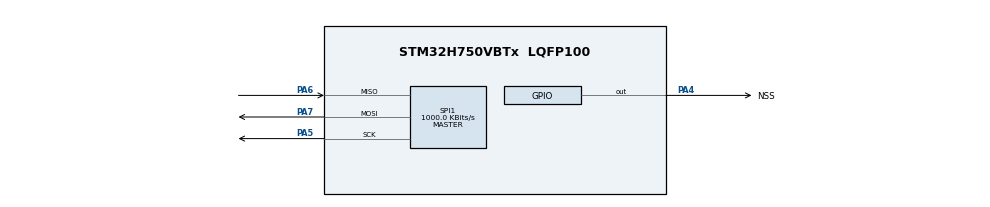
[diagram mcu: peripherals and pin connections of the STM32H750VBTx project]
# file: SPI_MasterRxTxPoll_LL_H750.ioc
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Mcu.Family=STM32H7
Mcu.Name=STM32H750VBTx
Mcu.Package=LQFP100
NVIC.PriorityGroup=NVIC_PRIORITYGROUP_4
PA13\ (JTMS/SWDIO).Mode=Serial_Wire
PA13\ (JTMS/SWDIO).Signal=DEBUG_JTMS-SWDIO
PA14\ (JTCK/SWCLK).Mode=Serial_Wire
PA14\ (JTCK/SWCLK).Signal=DEBUG_JTCK-SWCLK
PA4.GPIO_Label=NSS
PA4.Signal=GPIO_Output
PA5.Mode=Full_Duplex_Master
PA5.Signal=SPI1_SCK
PA6.Mode=Full_Duplex_Master
PA6.Signal=SPI1_MISO
PA7.Mode=Full_Duplex_Master
PA7.Signal=SPI1_MOSI
PH0-OSC_IN\ (PH0).Mode=HSE-External-Oscillator
PH0-OSC_IN\ (PH0).Signal=RCC_OSC_IN
PH1-OSC_OUT\ (PH1).Mode=HSE-External-Oscillator
PH1-OSC_OUT\ (PH1).Signal=RCC_OSC_OUT
ProjectManager.HeapSize=0x200
ProjectManager.StackSize=0x400
ProjectManager.TargetToolchain=STM32CubeIDE
RCC.ADCFreq_Value=128000000
RCC.APB1Freq_Value=120000000
RCC.APB2Freq_Value=120000000
RCC.APB3Freq_Value=120000000
RCC.APB4Freq_Value=120000000
RCC.CortexFreq_Value=240000000
RCC.DIVM1=25
RCC.DIVM2=25
RCC.DIVN1=480
RCC.DIVN2=256
RCC.HCLKFreq_Value=120000000
RCC.HPRE=RCC_HCLK_DIV2
RCC.PLLSourceVirtual=RCC_PLLSOURCE_HSE
RCC.SPI123CLockSelection=RCC_SPI123CLKSOURCE_PLL2
RCC.SYSCLKFreq_VALUE=240000000
RCC.SYSCLKSource=RCC_SYSCLKSOURCE_PLLCLK
RCC.USBFreq_Value=240000000
SPI1.BaudRatePrescaler=SPI_BAUDRATEPRESCALER_128
SPI1.CLKPolarity=SPI_POLARITY_HIGH
SPI1.CalculateBaudRate=1000.0 KBits/s
SPI1.DataSize=SPI_DATASIZE_8BIT
SPI1.Direction=SPI_DIRECTION_2LINES
SPI1.Mode=SPI_MODE_MASTER
SPI1.NSSPolarity=SPI_NSS_POLARITY_HIGH
SPI1.VirtualType=VM_MASTER
board=custom

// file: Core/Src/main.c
/* USER CODE BEGIN Header */
/**
  ******************************************************************************
  * @file           : main.c
  * @brief          : Main program body
  ******************************************************************************
  * @attention
  *
  * Copyright (c) 2023 STMicroelectronics.
  * All rights reserved.
  *
  * This software is licensed under terms that can be found in the LICENSE file
  * in the root directory of this software component.
  * If no LICENSE file comes with this software, it is provided AS-IS.
  *
  ******************************************************************************
  */
/* USER CODE END Header */
#include "main.h"

void SystemClock_Config(void);
void PeriphCommonClock_Config(void);
static void MX_GPIO_Init(void);
static void MX_SPI1_Init(void);

/* USER CODE BEGIN 0 */

// SPI写读一字节函数
uint8_t SPI_WriteReadBytes(SPI_TypeDef *SPIx, uint8_t TxData)
{
	while (!LL_SPI_IsActiveFlag_TXP(SPIx)) { } // 等待可写

	LL_SPI_TransmitData8(SPI1, TxData); // 写入一字节数据

	while (!LL_SPI_IsActiveFlag_RXP(SPIx)){ } // 等待可读

	return LL_SPI_ReceiveData8(SPIx); // 读取一字节数据
}

/* USER CODE END 0 */

int main(void)
{

  /* MCU Configuration--------------------------------------------------------*/

  /* Reset of all peripherals, Initializes the Flash interface and the Systick. */
  LL_APB4_GRP1_EnableClock(LL_APB4_GRP1_PERIPH_SYSCFG);

  /* System interrupt init*/
  NVIC_SetPriorityGrouping(NVIC_PRIORITYGROUP_4);

  /* SysTick_IRQn interrupt configuration */
  NVIC_SetPriority(SysTick_IRQn, NVIC_EncodePriority(NVIC_GetPriorityGrouping(),15, 0));

  /* Configure the system clock */
  SystemClock_Config();

/* Configure the peripherals common clocks */
  PeriphCommonClock_Config();

  /* Initialize all configured peripherals */
  MX_GPIO_Init();
  MX_SPI1_Init();

  /* Infinite loop */
  /* USER CODE BEGIN WHILE */

  LL_SPI_Enable(SPI1); // 使能SPI
  LL_SPI_StartMasterTransfer(SPI1); // 开启主机传输模式

  while (1)
  {
	  LL_GPIO_ResetOutputPin(GPIOA, LL_GPIO_PIN_4);
	  for(int i = 0; i < 256; i++)
	  {
		  SPI_WriteReadBytes(SPI1, i);
	  }
	  LL_GPIO_SetOutputPin(GPIOA, LL_GPIO_PIN_4);

	  LL_mDelay(1);

    /* USER CODE END WHILE */

  }
}

void SystemClock_Config(void)
{
  LL_FLASH_SetLatency(LL_FLASH_LATENCY_2);
  while(LL_FLASH_GetLatency()!= LL_FLASH_LATENCY_2)
  {
  }
  LL_PWR_ConfigSupply(LL_PWR_LDO_SUPPLY);
  LL_PWR_SetRegulVoltageScaling(LL_PWR_REGU_VOLTAGE_SCALE2);
  while (LL_PWR_IsActiveFlag_VOS() == 0)
  {
  }
  LL_RCC_HSE_Enable();

   /* Wait till HSE is ready */
  while(LL_RCC_HSE_IsReady() != 1)
  {

  }
  LL_RCC_PLL_SetSource(LL_RCC_PLLSOURCE_HSE);
  LL_RCC_PLL1P_Enable();
  LL_RCC_PLL1R_Enable();
  LL_RCC_PLL1_SetVCOInputRange(LL_RCC_PLLINPUTRANGE_1_2);
  LL_RCC_PLL1_SetVCOOutputRange(LL_RCC_PLLVCORANGE_WIDE);
  LL_RCC_PLL1_SetM(25);
  LL_RCC_PLL1_SetN(480);
  LL_RCC_PLL1_SetP(2);
  LL_RCC_PLL1_SetQ(2);
  LL_RCC_PLL1_SetR(2);
  LL_RCC_PLL1_Enable();

   /* Wait till PLL is ready */
  while(LL_RCC_PLL1_IsReady() != 1)
  {
  }

   /* Intermediate AHB prescaler 2 when target frequency clock is higher than 80 MHz */
   LL_RCC_SetAHBPrescaler(LL_RCC_AHB_DIV_2);

  LL_RCC_SetSysClkSource(LL_RCC_SYS_CLKSOURCE_PLL1);

   /* Wait till System clock is ready */
  while(LL_RCC_GetSysClkSource() != LL_RCC_SYS_CLKSOURCE_STATUS_PLL1)
  {

  }
  LL_RCC_SetSysPrescaler(LL_RCC_SYSCLK_DIV_1);
  LL_RCC_SetAHBPrescaler(LL_RCC_AHB_DIV_2);
  LL_RCC_SetAPB1Prescaler(LL_RCC_APB1_DIV_1);
  LL_RCC_SetAPB2Prescaler(LL_RCC_APB2_DIV_1);
  LL_RCC_SetAPB3Prescaler(LL_RCC_APB3_DIV_1);
  LL_RCC_SetAPB4Prescaler(LL_RCC_APB4_DIV_1);

  LL_Init1msTick(240000000);

  LL_SetSystemCoreClock(240000000);
}

void PeriphCommonClock_Config(void)
{
  LL_RCC_PLL2P_Enable();
  LL_RCC_PLL2_SetVCOInputRange(LL_RCC_PLLINPUTRANGE_1_2);
  LL_RCC_PLL2_SetVCOOutputRange(LL_RCC_PLLVCORANGE_WIDE);
  LL_RCC_PLL2_SetM(25);
  LL_RCC_PLL2_SetN(256);
  LL_RCC_PLL2_SetP(2);
  LL_RCC_PLL2_SetQ(2);
  LL_RCC_PLL2_SetR(2);
  LL_RCC_PLL2_Enable();

   /* Wait till PLL is ready */
  while(LL_RCC_PLL2_IsReady() != 1)
  {
  }

}

static void MX_SPI1_Init(void)
{

  LL_SPI_InitTypeDef SPI_InitStruct = {0};

  LL_GPIO_InitTypeDef GPIO_InitStruct = {0};

  LL_RCC_SetSPIClockSource(LL_RCC_SPI123_CLKSOURCE_PLL2P);

  /* Peripheral clock enable */
  LL_APB2_GRP1_EnableClock(LL_APB2_GRP1_PERIPH_SPI1);

  LL_AHB4_GRP1_EnableClock(LL_AHB4_GRP1_PERIPH_GPIOA);
  /**SPI1 GPIO Configuration
  PA5   ------> SPI1_SCK
  PA6   ------> SPI1_MISO
  PA7   ------> SPI1_MOSI
  */
  GPIO_InitStruct.Pin = LL_GPIO_PIN_5|LL_GPIO_PIN_6|LL_GPIO_PIN_7;
  GPIO_InitStruct.Mode = LL_GPIO_MODE_ALTERNATE;
  GPIO_InitStruct.Speed = LL_GPIO_SPEED_FREQ_LOW;
  GPIO_InitStruct.OutputType = LL_GPIO_OUTPUT_PUSHPULL;
  GPIO_InitStruct.Pull = LL_GPIO_PULL_NO;
  GPIO_InitStruct.Alternate = LL_GPIO_AF_5;
  LL_GPIO_Init(GPIOA, &GPIO_InitStruct);

  /* SPI1 parameter configuration*/
  SPI_InitStruct.TransferDirection = LL_SPI_FULL_DUPLEX;
  SPI_InitStruct.Mode = LL_SPI_MODE_MASTER;
  SPI_InitStruct.DataWidth = LL_SPI_DATAWIDTH_8BIT;
  SPI_InitStruct.ClockPolarity = LL_SPI_POLARITY_HIGH;
  SPI_InitStruct.ClockPhase = LL_SPI_PHASE_1EDGE;
  SPI_InitStruct.NSS = LL_SPI_NSS_SOFT;
  SPI_InitStruct.BaudRate = LL_SPI_BAUDRATEPRESCALER_DIV128;
  SPI_InitStruct.BitOrder = LL_SPI_MSB_FIRST;
  SPI_InitStruct.CRCCalculation = LL_SPI_CRCCALCULATION_DISABLE;
  SPI_InitStruct.CRCPoly = 0x0;
  LL_SPI_Init(SPI1, &SPI_InitStruct);
  LL_SPI_SetStandard(SPI1, LL_SPI_PROTOCOL_MOTOROLA);
  LL_SPI_EnableNSSPulseMgt(SPI1);

}

static void MX_GPIO_Init(void)
{
  LL_GPIO_InitTypeDef GPIO_InitStruct = {0};

  /* GPIO Ports Clock Enable */
  LL_AHB4_GRP1_EnableClock(LL_AHB4_GRP1_PERIPH_GPIOH);
  LL_AHB4_GRP1_EnableClock(LL_AHB4_GRP1_PERIPH_GPIOA);

  /**/
  LL_GPIO_ResetOutputPin(NSS_GPIO_Port, NSS_Pin);

  /**/
  GPIO_InitStruct.Pin = NSS_Pin;
  GPIO_InitStruct.Mode = LL_GPIO_MODE_OUTPUT;
  GPIO_InitStruct.Speed = LL_GPIO_SPEED_FREQ_LOW;
  GPIO_InitStruct.OutputType = LL_GPIO_OUTPUT_PUSHPULL;
  GPIO_InitStruct.Pull = LL_GPIO_PULL_NO;
  LL_GPIO_Init(NSS_GPIO_Port, &GPIO_InitStruct);

}

void Error_Handler(void)
{
  __disable_irq();
  while (1)
  {
  }
}
